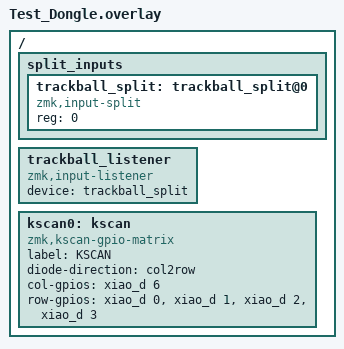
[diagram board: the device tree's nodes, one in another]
#include "Test.dtsi"
// #include "Test_trackball.dtsi"

/*input-split*/
/ {
    split_inputs {
        #address-cells = <1>;
        #size-cells = <0>;

        trackball_split: trackball_split@0 {
            compatible = "zmk,input-split";
            reg = <0>;
        };
    };

    trackball_listener: trackball_listener {
        compatible = "zmk,input-listener";
        status = "disabled";
        device = <&trackball_split>;
    };
};

/ {
    kscan0: kscan {
        compatible = "zmk,kscan-gpio-matrix";
        label = "KSCAN";
        diode-direction = "col2row";
        col-gpios
            = <&xiao_d 6 GPIO_ACTIVE_HIGH>
            ;
        row-gpios
        = <&xiao_d 0 (GPIO_ACTIVE_HIGH | GPIO_PULL_DOWN)>
        , <&xiao_d 1 (GPIO_ACTIVE_HIGH | GPIO_PULL_DOWN)>
        , <&xiao_d 2 (GPIO_ACTIVE_HIGH | GPIO_PULL_DOWN)>
        , <&xiao_d 3 (GPIO_ACTIVE_HIGH | GPIO_PULL_DOWN)>
        ;
    };
};

// &xiao_serial { status = "disabled"; };

&trackball_listener {
    status = "okay";
};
